# BL602 register map
Vendor: bouffalolab; Series: WiFi BT
Registers are 32-bit, read-write, reset 0x0 unless marked. A register's access mark holds for its fields unless they carry their own. Offsets are from the block's base; [hi:lo] are bit positions; {n}, {i} and the like mark numbered series.

## TZC_NSEC
Base 0x40006000
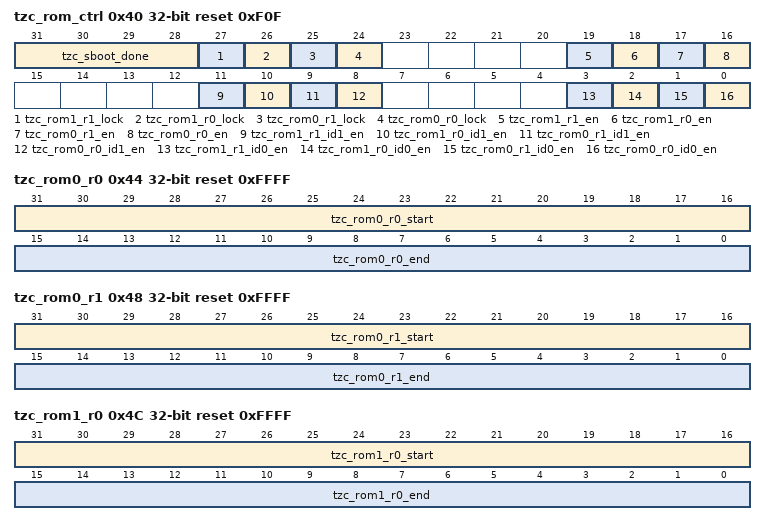
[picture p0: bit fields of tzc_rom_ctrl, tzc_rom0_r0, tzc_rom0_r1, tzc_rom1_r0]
0x40 tzc_rom_ctrl ro reset 0xF0F
  [31:28] tzc_sboot_done, [27] tzc_rom1_r1_lock, [26] tzc_rom1_r0_lock, [25] tzc_rom0_r1_lock, [24] tzc_rom0_r0_lock, [19] tzc_rom1_r1_en, [18] tzc_rom1_r0_en, [17] tzc_rom0_r1_en, [16] tzc_rom0_r0_en, [11] tzc_rom1_r1_id1_en, [10] tzc_rom1_r0_id1_en, [9] tzc_rom0_r1_id1_en, [8] tzc_rom0_r0_id1_en, [3] tzc_rom1_r1_id0_en, [2] tzc_rom1_r0_id0_en, [1] tzc_rom0_r1_id0_en, [0] tzc_rom0_r0_id0_en
0x44 tzc_rom0_r0 ro reset 0xFFFF
  [31:16] tzc_rom0_r0_start, [15:0] tzc_rom0_r0_end
0x48 tzc_rom0_r1 ro reset 0xFFFF
  [31:16] tzc_rom0_r1_start, [15:0] tzc_rom0_r1_end
0x4C tzc_rom1_r0 ro reset 0xFFFF
  [31:16] tzc_rom1_r0_start, [15:0] tzc_rom1_r0_end
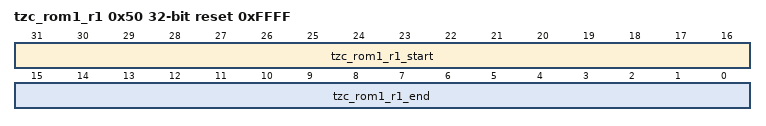
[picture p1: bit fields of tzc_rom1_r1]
0x50 tzc_rom1_r1 ro reset 0xFFFF
  [31:16] tzc_rom1_r1_start, [15:0] tzc_rom1_r1_end

## EF_DATA_0
Base 0x40007000
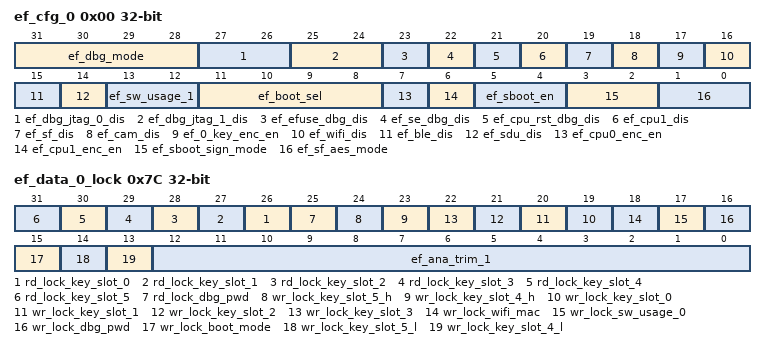
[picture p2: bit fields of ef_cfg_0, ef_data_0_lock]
0x00 ef_cfg_0
  [31:28] ef_dbg_mode, [27:26] ef_dbg_jtag_0_dis, [25:24] ef_dbg_jtag_1_dis, [23] ef_efuse_dbg_dis, [22] ef_se_dbg_dis, [21] ef_cpu_rst_dbg_dis, [20] ef_cpu1_dis, [19] ef_sf_dis, [18] ef_cam_dis, [17] ef_0_key_enc_en, [16] ef_wifi_dis, [15] ef_ble_dis, [14] ef_sdu_dis, [13:12] ef_sw_usage_1, [11:8] ef_boot_sel, [7] ef_cpu0_enc_en, [6] ef_cpu1_enc_en, [5:4] ef_sboot_en, [3:2] ef_sboot_sign_mode, [1:0] ef_sf_aes_mode
0x04 ef_dbg_pwd_low
0x08 ef_dbg_pwd_high
0x0C ef_ana_trim_0
0x10 ef_sw_usage_0
0x14 ef_wifi_mac_low
0x18 ef_wifi_mac_high
{0x1C+0x10*i} ef_key_slot_{i}_w0 (i=0..5)
{0x20+0x10*i} ef_key_slot_{i}_w1 (i=0..5)
{0x24+0x10*i} ef_key_slot_{i}_w2 (i=0..5)
{0x28+0x10*i} ef_key_slot_{i}_w3 (i=0..5)
0x7C ef_data_0_lock
  [n+26] rd_lock_key_slot_{n} (n=0..5), [25] rd_lock_dbg_pwd, [24] wr_lock_key_slot_5_h, [23] wr_lock_key_slot_4_h, [n+19] wr_lock_key_slot_{n} (n=0..3), [18] wr_lock_wifi_mac, [17] wr_lock_sw_usage_0, [16] wr_lock_dbg_pwd, [15] wr_lock_boot_mode, [14] wr_lock_key_slot_5_l, [13] wr_lock_key_slot_4_l, [12:0] ef_ana_trim_1

## EF_DATA_1
Base 0x40007080
{0x0+4i} reg_key_slot_6_w{i} (i=0..3)
{0x10+4i} reg_key_slot_7_w{i} (i=0..3)
{0x20+4i} reg_key_slot_8_w{i} (i=0..3)
{0x30+4i} reg_key_slot_9_w{i} (i=0..3)
{0x40+4i} reg_key_slot_10_w{i} (i=0..3)
{0x50+4i} reg_key_slot_11_w{i} (i=0..3)
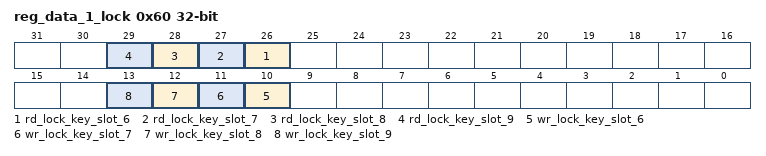
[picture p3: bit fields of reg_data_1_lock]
0x60 reg_data_1_lock
  [n+20] rd_lock_key_slot_{n} (n=6..9), [n+4] wr_lock_key_slot_{n} (n=6..9)

## EF_CTRL — eFuse memory control
Base 0x40007800
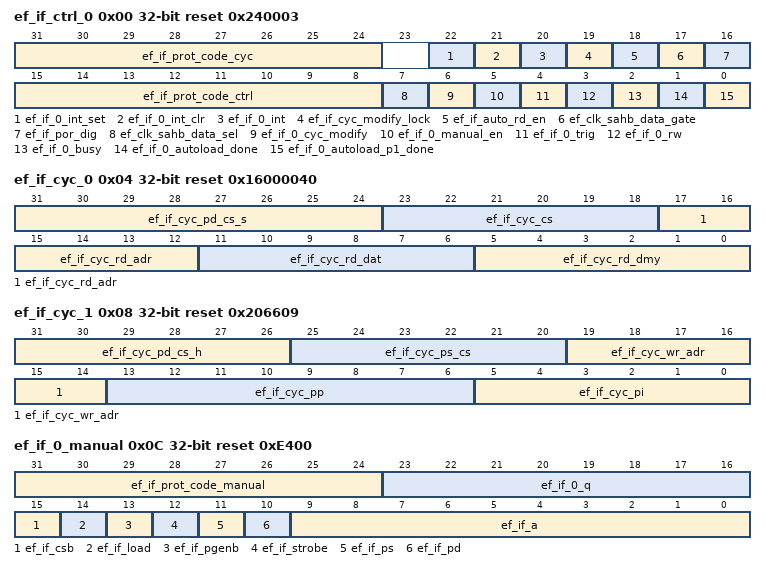
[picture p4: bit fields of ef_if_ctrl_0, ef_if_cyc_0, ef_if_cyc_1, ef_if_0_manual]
0x00 ef_if_ctrl_0 reset 0x240003
  [31:24] ef_if_prot_code_cyc, [22] ef_if_0_int_set, [21] ef_if_0_int_clr, [20] ef_if_0_int ro, [19] ef_if_cyc_modify_lock, [18] ef_if_auto_rd_en, [17] ef_clk_sahb_data_gate, [16] ef_if_por_dig, [15:8] ef_if_prot_code_ctrl, [7] ef_clk_sahb_data_sel, [6] ef_if_0_cyc_modify, [5] ef_if_0_manual_en, [4] ef_if_0_trig, [3] ef_if_0_rw, [2] ef_if_0_busy ro, [1] ef_if_0_autoload_done ro, [0] ef_if_0_autoload_p1_done ro
0x04 ef_if_cyc_0 reset 0x16000040
  [31:24] ef_if_cyc_pd_cs_s, [23:18] ef_if_cyc_cs, [17:12] ef_if_cyc_rd_adr, [11:6] ef_if_cyc_rd_dat, [5:0] ef_if_cyc_rd_dmy
0x08 ef_if_cyc_1 reset 0x206609
  [31:26] ef_if_cyc_pd_cs_h, [25:20] ef_if_cyc_ps_cs, [19:14] ef_if_cyc_wr_adr, [13:6] ef_if_cyc_pp, [5:0] ef_if_cyc_pi
0x0C ef_if_0_manual reset 0xE400
  [31:24] ef_if_prot_code_manual, [23:16] ef_if_0_q ro, [15] ef_if_csb, [14] ef_if_load, [13] ef_if_pgenb, [12] ef_if_strobe, [11] ef_if_ps, [10] ef_if_pd, [9:0] ef_if_a
0x10 ef_if_0_status reset 0xE400
  [31:0] ef_if_0_status ro
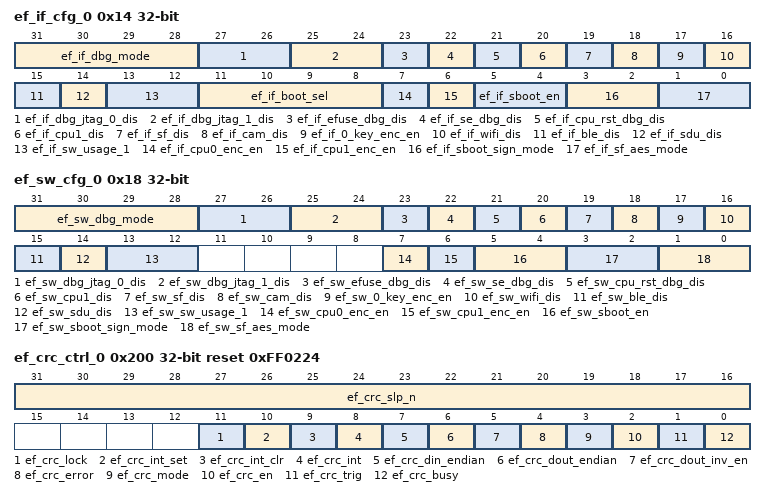
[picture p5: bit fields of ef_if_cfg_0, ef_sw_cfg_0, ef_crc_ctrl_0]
0x14 ef_if_cfg_0 ro
  [31:28] ef_if_dbg_mode, [27:26] ef_if_dbg_jtag_0_dis, [25:24] ef_if_dbg_jtag_1_dis, [23] ef_if_efuse_dbg_dis, [22] ef_if_se_dbg_dis, [21] ef_if_cpu_rst_dbg_dis, [20] ef_if_cpu1_dis, [19] ef_if_sf_dis, [18] ef_if_cam_dis, [17] ef_if_0_key_enc_en, [16] ef_if_wifi_dis, [15] ef_if_ble_dis, [14] ef_if_sdu_dis, [13:12] ef_if_sw_usage_1, [11:8] ef_if_boot_sel, [7] ef_if_cpu0_enc_en, [6] ef_if_cpu1_enc_en, [5:4] ef_if_sboot_en, [3:2] ef_if_sboot_sign_mode, [1:0] ef_if_sf_aes_mode
0x18 ef_sw_cfg_0
  [31:28] ef_sw_dbg_mode, [27:26] ef_sw_dbg_jtag_0_dis, [25:24] ef_sw_dbg_jtag_1_dis, [23] ef_sw_efuse_dbg_dis, [22] ef_sw_se_dbg_dis, [21] ef_sw_cpu_rst_dbg_dis, [20] ef_sw_cpu1_dis, [19] ef_sw_sf_dis, [18] ef_sw_cam_dis, [17] ef_sw_0_key_enc_en, [16] ef_sw_wifi_dis, [15] ef_sw_ble_dis, [14] ef_sw_sdu_dis, [13:12] ef_sw_sw_usage_1, [7] ef_sw_cpu0_enc_en, [6] ef_sw_cpu1_enc_en, [5:4] ef_sw_sboot_en, [3:2] ef_sw_sboot_sign_mode, [1:0] ef_sw_sf_aes_mode
0x1C ef_reserved
0x20 ef_if_ana_trim_0
  [31:0] ef_if_ana_trim_0 ro
0x24 ef_if_sw_usage_0
  [31:0] ef_if_sw_usage_0 ro
0x200 ef_crc_ctrl_0 reset 0xFF0224
  [31:16] ef_crc_slp_n, [11] ef_crc_lock, [10] ef_crc_int_set, [9] ef_crc_int_clr, [8] ef_crc_int ro, [7] ef_crc_din_endian, [6] ef_crc_dout_endian, [5] ef_crc_dout_inv_en, [4] ef_crc_error ro, [3] ef_crc_mode, [2] ef_crc_en, [1] ef_crc_trig, [0] ef_crc_busy ro
0x204 ef_crc_ctrl_1 reset 0xFFFFFFFF
  [31:0] ef_crc_data_0_en
0x208 ef_crc_ctrl_2 reset 0xFFFFFFFF
  [31:0] ef_crc_data_1_en
0x20C ef_crc_ctrl_3 reset 0xFFFFFFFF
  [31:0] ef_crc_iv
0x210 ef_crc_ctrl_4 reset 0xC2A8FA9D
  [31:0] ef_crc_golden
0x214 ef_crc_ctrl_5 reset 0xFFFFFFFF
  [31:0] ef_crc_dout ro
